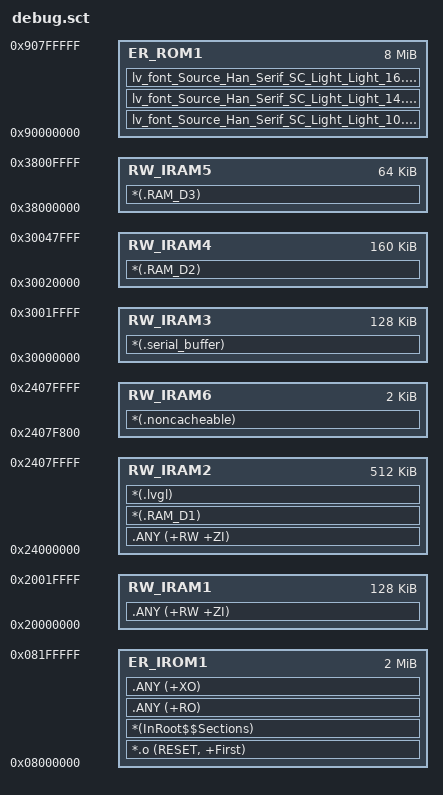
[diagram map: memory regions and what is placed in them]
; *************************************************************
; *** Scatter-Loading Description File generated by uVision ***
; *************************************************************

LR_IROM1 0x08000000 0x00200000  {    ; load region size_region
  ER_IROM1 0x08000000 0x00200000  {  ; load address = execution address
   *.o (RESET, +First)
   *(InRoot$$Sections)
   .ANY (+RO)
   .ANY (+XO)
  }
  
  RW_IRAM1 0x20000000 0x00020000  {  ; RW data
   .ANY (+RW +ZI)
  }
  
  RW_IRAM2 0x24000000 0x00080000  {
   .ANY (+RW +ZI)
   *(.RAM_D1)
   *(.lvgl)
  }
  
  RW_IRAM3 0x30000000 0x00020000  {  ; RW data
   *(.serial_buffer)
  }
  
  RW_IRAM4 0x30020000 0x00028000  {  ; RW data
   *(.RAM_D2)
  }
  
  RW_IRAM5 0x38000000 0x00010000  {  ; RW data
   *(.RAM_D3)
  }
  RW_IRAM6 0x24080000-0x800 0x800  {
   *(.noncacheable)
  }
  
}

LR_ROM1 0x90000000 0x00800000  {
  ER_ROM1 0x90000000 0x00800000  {  ; load address = execution address
    lv_font_Source_Han_Serif_SC_Light_Light_10.o (+RO)
    lv_font_Source_Han_Serif_SC_Light_Light_14.o (+RO)
    lv_font_Source_Han_Serif_SC_Light_Light_16.o (+RO)
  }
}
